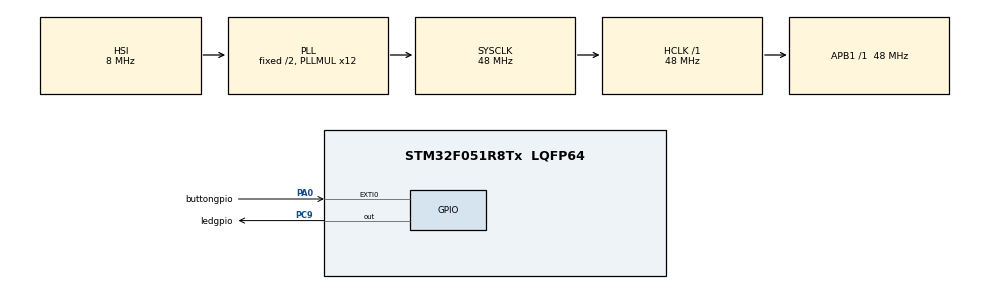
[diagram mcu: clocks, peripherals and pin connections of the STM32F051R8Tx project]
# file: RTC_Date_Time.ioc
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Mcu.Family=STM32F0
Mcu.Name=STM32F051R8Tx
Mcu.Package=LQFP64
NVIC.EXTI0_1_IRQn=true\:0\:0\:false\:false\:true\:true\:true
NVIC.RTC_IRQn=true\:0\:0\:false\:false\:true\:true\:true
PA0.GPIO_Label=buttongpio
PA0.GPIO_ModeDefaultEXTI=GPIO_MODE_IT_FALLING
PA0.Signal=GPXTI0
PA13.GPIO_Label=SWDIO
PA13.Mode=Serial_Wire
PA13.Signal=SYS_SWDIO
PA14.GPIO_Label=SWCLK
PA14.Mode=Serial_Wire
PA14.Signal=SYS_SWCLK
PC9.GPIO_Label=ledgpio
PC9.Signal=GPIO_Output
ProjectManager.HeapSize=0x200
ProjectManager.StackSize=0x400
ProjectManager.TargetToolchain=STM32CubeIDE
RCC.AHBFreq_Value=48000000
RCC.APB1Freq_Value=48000000
RCC.APB1TimFreq_Value=48000000
RCC.HCLKFreq_Value=48000000
RCC.PLLMUL=RCC_PLL_MUL12
RCC.SYSCLKFreq_VALUE=48000000
RCC.SYSCLKSource=RCC_SYSCLKSOURCE_PLLCLK
RTC.Alarm-Alarm\ A=RTC_ALARM_A
RTC.AlarmMaskDateWeekDay-Alarm\ A=RTC_ALARMMASK_DATEWEEKDAY
RTC.AlarmMaskHours-Alarm\ A=RTC_ALARMMASK_HOURS
RTC.AsynchPrediv=124
RTC.Date=12
RTC.Format=RTC_FORMAT_BIN
RTC.HourFormat=RTC_HOURFORMAT_12
RTC.Hours=12
RTC.Hours_A-Alarm\ A=1
RTC.Minutes=11
RTC.Minutes_A-Alarm\ A=12
RTC.Month=RTC_MONTH_JUNE
RTC.Seconds=10
RTC.Seconds_A-Alarm\ A=9
RTC.SynchPrediv=295
RTC.TimeFormat=RTC_HOURFORMAT12_PM
RTC.WeekDay=RTC_WEEKDAY_TUESDAY
RTC.Year=18
VP_RTC_VS_RTC_Activate.Mode=RTC_Enabled
VP_RTC_VS_RTC_Alarm_A_Intern.Mode=Alarm A
VP_RTC_VS_RTC_Calendar.Mode=RTC_Calendar
board=STM32F0DISCOVERY

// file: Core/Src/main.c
/* USER CODE BEGIN Header */
/**
  ******************************************************************************
  * @file           : main.c
  * @brief          : Main program body
  ******************************************************************************
  * @attention
  *
  * <h2><center>&copy; Copyright (c) 2021 STMicroelectronics.
  * All rights reserved.</center></h2>
  *
  * This software component is licensed by ST under BSD 3-Clause license,
  * the "License"; You may not use this file except in compliance with the
  * License. You may obtain a copy of the License at:
  *                        opensource.org/licenses/BSD-3-Clause
  *
  ******************************************************************************
  */
/* USER CODE END Header */
#include "main.h"

RTC_HandleTypeDef hrtc;

/* USER CODE BEGIN PV */

uint8_t readButtonPressed = 0;

uint8_t alarmInterruptFired = 0;

/* USER CODE END PV */

void SystemClock_Config(void);
static void MX_GPIO_Init(void);
static void MX_RTC_Init(void);
/* USER CODE BEGIN PFP */
static void readTimeAndDate(void);
/* USER CODE END PFP */

int main(void)
{

  /* MCU Configuration--------------------------------------------------------*/

  /* Reset of all peripherals, Initializes the Flash interface and the Systick. */
  HAL_Init();

  /* Configure the system clock */
  SystemClock_Config();

  /* Initialize all configured peripherals */
  MX_GPIO_Init();
  MX_RTC_Init();

  /* Infinite loop */
  /* USER CODE BEGIN WHILE */
  while (1)
  {
	  if(readButtonPressed == 1)
	  {
		  readButtonPressed = 0;
		  readTimeAndDate();
	  }

	  if(alarmInterruptFired == 1)
	  {
		  alarmInterruptFired = 0;
		  HAL_GPIO_WritePin(buttongpio_GPIO_Port, buttongpio_Pin, GPIO_PIN_SET);
		  HAL_Delay(2000);
		  HAL_GPIO_WritePin(buttongpio_GPIO_Port, buttongpio_Pin, GPIO_PIN_RESET);
	  }
    /* USER CODE END WHILE */

  }
}

void SystemClock_Config(void)
{
  RCC_OscInitTypeDef RCC_OscInitStruct = {0};
  RCC_ClkInitTypeDef RCC_ClkInitStruct = {0};
  RCC_PeriphCLKInitTypeDef PeriphClkInit = {0};

  /** Initializes the RCC Oscillators according to the specified parameters
  * in the RCC_OscInitTypeDef structure.
  */
  RCC_OscInitStruct.OscillatorType = RCC_OSCILLATORTYPE_HSI|RCC_OSCILLATORTYPE_LSI;
  RCC_OscInitStruct.HSIState = RCC_HSI_ON;
  RCC_OscInitStruct.HSICalibrationValue = RCC_HSICALIBRATION_DEFAULT;
  RCC_OscInitStruct.LSIState = RCC_LSI_ON;
  RCC_OscInitStruct.PLL.PLLState = RCC_PLL_ON;
  RCC_OscInitStruct.PLL.PLLSource = RCC_PLLSOURCE_HSI;
  RCC_OscInitStruct.PLL.PLLMUL = RCC_PLL_MUL12;
  RCC_OscInitStruct.PLL.PREDIV = RCC_PREDIV_DIV1;
  if (HAL_RCC_OscConfig(&RCC_OscInitStruct) != HAL_OK)
  {
    Error_Handler();
  }
  /** Initializes the CPU, AHB and APB buses clocks
  */
  RCC_ClkInitStruct.ClockType = RCC_CLOCKTYPE_HCLK|RCC_CLOCKTYPE_SYSCLK
                              |RCC_CLOCKTYPE_PCLK1;
  RCC_ClkInitStruct.SYSCLKSource = RCC_SYSCLKSOURCE_PLLCLK;
  RCC_ClkInitStruct.AHBCLKDivider = RCC_SYSCLK_DIV1;
  RCC_ClkInitStruct.APB1CLKDivider = RCC_HCLK_DIV1;

  if (HAL_RCC_ClockConfig(&RCC_ClkInitStruct, FLASH_LATENCY_1) != HAL_OK)
  {
    Error_Handler();
  }
  PeriphClkInit.PeriphClockSelection = RCC_PERIPHCLK_RTC;
  PeriphClkInit.RTCClockSelection = RCC_RTCCLKSOURCE_LSI;
  if (HAL_RCCEx_PeriphCLKConfig(&PeriphClkInit) != HAL_OK)
  {
    Error_Handler();
  }
}

static void MX_RTC_Init(void)
{

  RTC_TimeTypeDef sTime = {0};
  RTC_DateTypeDef sDate = {0};
  RTC_AlarmTypeDef sAlarm = {0};

  /** Initialize RTC Only
  */
  hrtc.Instance = RTC;
  hrtc.Init.HourFormat = RTC_HOURFORMAT_12;
  hrtc.Init.AsynchPrediv = 124;
  hrtc.Init.SynchPrediv = 295;
  hrtc.Init.OutPut = RTC_OUTPUT_DISABLE;
  hrtc.Init.OutPutPolarity = RTC_OUTPUT_POLARITY_HIGH;
  hrtc.Init.OutPutType = RTC_OUTPUT_TYPE_OPENDRAIN;
  if (HAL_RTC_Init(&hrtc) != HAL_OK)
  {
    Error_Handler();
  }

  /** Initialize RTC and set the Time and Date
  */
  sTime.Hours = 12;
  sTime.Minutes = 11;
  sTime.Seconds = 10;
  sTime.TimeFormat = RTC_HOURFORMAT12_PM;
  sTime.DayLightSaving = RTC_DAYLIGHTSAVING_NONE;
  sTime.StoreOperation = RTC_STOREOPERATION_RESET;
  if (HAL_RTC_SetTime(&hrtc, &sTime, RTC_FORMAT_BIN) != HAL_OK)
  {
    Error_Handler();
  }
  sDate.WeekDay = RTC_WEEKDAY_TUESDAY;
  sDate.Month = RTC_MONTH_JUNE;
  sDate.Date = 12;
  sDate.Year = 18;

  if (HAL_RTC_SetDate(&hrtc, &sDate, RTC_FORMAT_BIN) != HAL_OK)
  {
    Error_Handler();
  }
  /** Enable the Alarm A
  */
  sAlarm.AlarmTime.Hours = 1;
  sAlarm.AlarmTime.Minutes = 12;
  sAlarm.AlarmTime.Seconds = 9;
  sAlarm.AlarmTime.SubSeconds = 0;
  sAlarm.AlarmTime.TimeFormat = RTC_HOURFORMAT12_PM;
  sAlarm.AlarmTime.DayLightSaving = RTC_DAYLIGHTSAVING_NONE;
  sAlarm.AlarmTime.StoreOperation = RTC_STOREOPERATION_RESET;
  sAlarm.AlarmMask = RTC_ALARMMASK_DATEWEEKDAY|RTC_ALARMMASK_HOURS;
  sAlarm.AlarmSubSecondMask = RTC_ALARMSUBSECONDMASK_ALL;
  sAlarm.AlarmDateWeekDaySel = RTC_ALARMDATEWEEKDAYSEL_DATE;
  sAlarm.AlarmDateWeekDay = 1;
  sAlarm.Alarm = RTC_ALARM_A;
  if (HAL_RTC_SetAlarm_IT(&hrtc, &sAlarm, RTC_FORMAT_BIN) != HAL_OK)
  {
    Error_Handler();
  }
  /* USER CODE BEGIN RTC_Init 2 */
  HAL_NVIC_SetPriority(RTC_IRQn, 3, 0);
  HAL_NVIC_EnableIRQ(RTC_IRQn);
  /* USER CODE END RTC_Init 2 */

}

static void MX_GPIO_Init(void)
{
  GPIO_InitTypeDef GPIO_InitStruct = {0};

  /* GPIO Ports Clock Enable */
  __HAL_RCC_GPIOA_CLK_ENABLE();
  __HAL_RCC_GPIOC_CLK_ENABLE();

  /*Configure GPIO pin Output Level */
  HAL_GPIO_WritePin(ledgpio_GPIO_Port, ledgpio_Pin, GPIO_PIN_RESET);

  /*Configure GPIO pin : buttongpio_Pin */
  GPIO_InitStruct.Pin = buttongpio_Pin;
  GPIO_InitStruct.Mode = GPIO_MODE_IT_FALLING;
  GPIO_InitStruct.Pull = GPIO_NOPULL;
  HAL_GPIO_Init(buttongpio_GPIO_Port, &GPIO_InitStruct);

  /*Configure GPIO pin : ledgpio_Pin */
  GPIO_InitStruct.Pin = ledgpio_Pin;
  GPIO_InitStruct.Mode = GPIO_MODE_OUTPUT_PP;
  GPIO_InitStruct.Pull = GPIO_NOPULL;
  GPIO_InitStruct.Speed = GPIO_SPEED_FREQ_LOW;
  HAL_GPIO_Init(ledgpio_GPIO_Port, &GPIO_InitStruct);

  /* EXTI interrupt init*/
  HAL_NVIC_SetPriority(EXTI0_1_IRQn, 0, 0);
  HAL_NVIC_EnableIRQ(EXTI0_1_IRQn);

}

/* USER CODE BEGIN 4 */

void HAL_RTC_AlarmAEventCallback(RTC_HandleTypeDef *hrtc)
{
	alarmInterruptFired = 1;
}

void HAL_GPIO_EXTI_Callback(uint16_t GPIO_Pin)
{
	readButtonPressed = 1;
}

void RTC_AlarmConfig(void)
{
	RTC_AlarmTypeDef alarmA;

	//xx:45:09
	alarmA.Alarm = RTC_ALARM_A;
	alarmA.AlarmTime.Minutes = 45;
	alarmA.AlarmTime.Seconds = 9;
	alarmA.AlarmMask = RTC_ALARMMASK_HOURS | RTC_ALARMMASK_DATEWEEKDAY;
	alarmA.AlarmSubSecondMask = RTC_ALARMSUBSECONDMASK_NONE;

	if (HAL_RTC_SetAlarm_IT(&hrtc, &alarmA, RTC_FORMAT_BIN) != HAL_OK)
	{
		Error_Handler();
	}
}

static void readTimeAndDate(void)
{
	RTC_TimeTypeDef RTC_TimeRead;
	RTC_DateTypeDef RTC_DateRead;

	//MX_RTC_Init();

	HAL_RTC_GetTime(&hrtc, &RTC_TimeRead, RTC_FORMAT_BIN);
	HAL_RTC_GetDate(&hrtc, &RTC_DateRead, RTC_FORMAT_BIN);

//	RTC_AlarmConfig();

}
/* USER CODE END 4 */

void Error_Handler(void)
{
}

/************************ (C) COPYRIGHT STMicroelectronics *****END OF FILE****/
